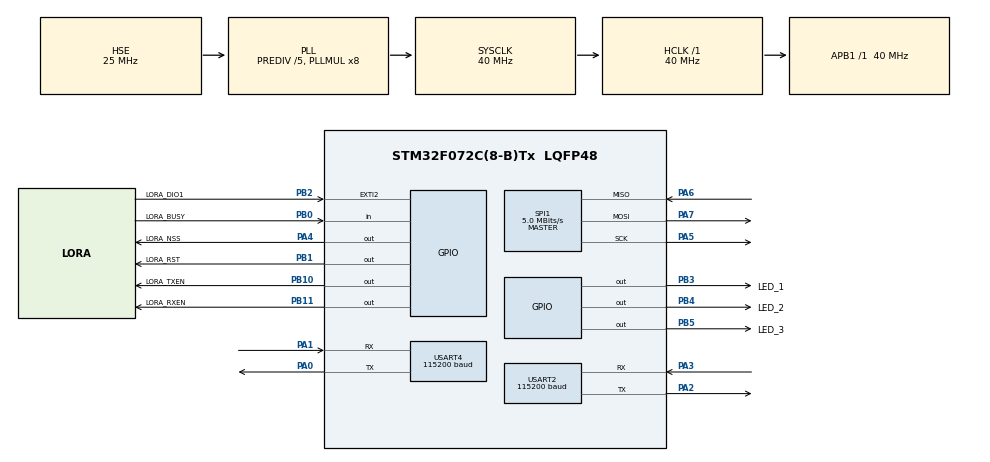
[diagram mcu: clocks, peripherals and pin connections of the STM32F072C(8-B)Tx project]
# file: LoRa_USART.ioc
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Dma.Request0=USART2_RX
Dma.Request1=USART2_TX
Dma.Request2=SPI1_RX
Dma.Request3=SPI1_TX
Dma.SPI1_RX.2.Direction=DMA_PERIPH_TO_MEMORY
Dma.SPI1_RX.2.Instance=DMA1_Channel2
Dma.SPI1_RX.2.MemDataAlignment=DMA_MDATAALIGN_BYTE
Dma.SPI1_RX.2.MemInc=DMA_MINC_ENABLE
Dma.SPI1_RX.2.Mode=DMA_NORMAL
Dma.SPI1_RX.2.PeriphDataAlignment=DMA_PDATAALIGN_BYTE
Dma.SPI1_RX.2.PeriphInc=DMA_PINC_DISABLE
Dma.SPI1_RX.2.Priority=DMA_PRIORITY_HIGH
Dma.SPI1_TX.3.Direction=DMA_MEMORY_TO_PERIPH
Dma.SPI1_TX.3.Instance=DMA1_Channel3
Dma.SPI1_TX.3.MemDataAlignment=DMA_MDATAALIGN_BYTE
Dma.SPI1_TX.3.MemInc=DMA_MINC_ENABLE
Dma.SPI1_TX.3.Mode=DMA_NORMAL
Dma.SPI1_TX.3.PeriphDataAlignment=DMA_PDATAALIGN_BYTE
Dma.SPI1_TX.3.PeriphInc=DMA_PINC_DISABLE
Dma.SPI1_TX.3.Priority=DMA_PRIORITY_HIGH
Dma.USART2_RX.0.Direction=DMA_PERIPH_TO_MEMORY
Dma.USART2_RX.0.Instance=DMA1_Channel5
Dma.USART2_RX.0.MemDataAlignment=DMA_MDATAALIGN_BYTE
Dma.USART2_RX.0.MemInc=DMA_MINC_ENABLE
Dma.USART2_RX.0.Mode=DMA_NORMAL
Dma.USART2_RX.0.PeriphDataAlignment=DMA_PDATAALIGN_BYTE
Dma.USART2_RX.0.PeriphInc=DMA_PINC_DISABLE
Dma.USART2_RX.0.Priority=DMA_PRIORITY_HIGH
Dma.USART2_TX.1.Direction=DMA_MEMORY_TO_PERIPH
Dma.USART2_TX.1.Instance=DMA1_Channel4
Dma.USART2_TX.1.MemDataAlignment=DMA_MDATAALIGN_BYTE
Dma.USART2_TX.1.MemInc=DMA_MINC_ENABLE
Dma.USART2_TX.1.Mode=DMA_NORMAL
Dma.USART2_TX.1.PeriphDataAlignment=DMA_PDATAALIGN_BYTE
Dma.USART2_TX.1.PeriphInc=DMA_PINC_DISABLE
Dma.USART2_TX.1.Priority=DMA_PRIORITY_HIGH
Mcu.Family=STM32F0
Mcu.Name=STM32F072C(8-B)Tx
Mcu.Package=LQFP48
NVIC.DMA1_Channel2_3_IRQn=true\:0\:0\:false\:false\:true\:false\:true\:true
NVIC.DMA1_Channel4_5_6_7_IRQn=true\:0\:0\:false\:false\:true\:false\:true\:true
NVIC.EXTI2_3_IRQn=true\:0\:0\:false\:false\:true\:true\:true\:true
NVIC.SPI1_IRQn=true\:0\:0\:false\:false\:true\:true\:true\:true
NVIC.USART2_IRQn=true\:0\:0\:false\:false\:true\:true\:true\:true
NVIC.USART3_4_IRQn=true\:0\:0\:false\:false\:true\:true\:true\:true
PA0.Mode=Asynchronous
PA0.Signal=USART4_TX
PA1.Mode=Asynchronous
PA1.Signal=USART4_RX
PA13.Mode=Serial_Wire
PA13.Signal=SYS_SWDIO
PA14.Mode=Serial_Wire
PA14.Signal=SYS_SWCLK
PA2.Mode=Asynchronous
PA2.Signal=USART2_TX
PA3.Mode=Asynchronous
PA3.Signal=USART2_RX
PA4.GPIO_Label=LORA_NSS
PA4.GPIO_Speed=GPIO_SPEED_FREQ_HIGH
PA4.Signal=GPIO_Output
PA5.Mode=Full_Duplex_Master
PA5.Signal=SPI1_SCK
PA6.Mode=Full_Duplex_Master
PA6.Signal=SPI1_MISO
PA7.Mode=Full_Duplex_Master
PA7.Signal=SPI1_MOSI
PB0.GPIO_Label=LORA_BUSY
PB0.Signal=GPIO_Input
PB1.GPIO_Label=LORA_RST
PB1.Signal=GPIO_Output
PB10.GPIO_Label=LORA_TXEN
PB10.GPIO_Speed=GPIO_SPEED_FREQ_HIGH
PB10.Signal=GPIO_Output
PB11.GPIO_Label=LORA_RXEN
PB11.GPIO_Speed=GPIO_SPEED_FREQ_HIGH
PB11.Signal=GPIO_Output
PB2.GPIO_Label=LORA_DIO1
PB2.Signal=GPXTI2
PB3.GPIO_Label=LED_1
PB3.Signal=GPIO_Output
PB4.GPIO_Label=LED_2
PB4.Signal=GPIO_Output
PB5.GPIO_Label=LED_3
PB5.Signal=GPIO_Output
PF0-OSC_IN.Mode=HSE-External-Oscillator
PF0-OSC_IN.Signal=RCC_OSC_IN
PF1-OSC_OUT.Mode=HSE-External-Oscillator
PF1-OSC_OUT.Signal=RCC_OSC_OUT
ProjectManager.HeapSize=0x200
ProjectManager.StackSize=0x400
ProjectManager.TargetToolchain=MDK-ARM V5.32
RCC.AHBFreq_Value=40000000
RCC.APB1Freq_Value=40000000
RCC.APB1TimFreq_Value=40000000
RCC.HCLKFreq_Value=40000000
RCC.HSE_VALUE=25000000
RCC.PLLDivider=RCC_PREDIV_DIV5
RCC.PLLMUL=RCC_PLL_MUL8
RCC.PLLSourceVirtual=RCC_PLLSOURCE_HSE
RCC.SYSCLKFreq_VALUE=40000000
RCC.SYSCLKSource=RCC_SYSCLKSOURCE_PLLCLK
SPI1.BaudRatePrescaler=SPI_BAUDRATEPRESCALER_8
SPI1.CalculateBaudRate=5.0 MBits/s
SPI1.DataSize=SPI_DATASIZE_8BIT
SPI1.Direction=SPI_DIRECTION_2LINES
SPI1.Mode=SPI_MODE_MASTER
SPI1.VirtualType=VM_MASTER
USART2.BaudRate=115200
USART2.VirtualMode-Asynchronous=VM_ASYNC
USART4.BaudRate=115200
USART4.VirtualMode-Asynchronous=VM_ASYNC
board=custom

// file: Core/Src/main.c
/* USER CODE BEGIN Header */
/**
  ******************************************************************************
  * @file           : main.c
  * @brief          : Main program body
  ******************************************************************************
  * @attention
  *
  * Copyright (c) 2026 STMicroelectronics.
  * All rights reserved.
  *
  * This software is licensed under terms that can be found in the LICENSE file
  * in the root directory of this software component.
  * If no LICENSE file comes with this software, it is provided AS-IS.
  *
  ******************************************************************************
  */
/* USER CODE END Header */
#include "main.h"
#include "dma.h"
#include "spi.h"
#include "usart.h"
#include "gpio.h"

/* USER CODE BEGIN Includes */
#include "app_bridge.h"
#include "myRadio.h"
#include "sx126x.h"
/* USER CODE END Includes */

void SystemClock_Config(void);

int main(void)
{

  /* MCU Configuration--------------------------------------------------------*/

  /* Reset of all peripherals, Initializes the Flash interface and the Systick. */
  HAL_Init();

  /* Configure the system clock */
  SystemClock_Config();

  /* Initialize all configured peripherals */
  MX_GPIO_Init();
  MX_DMA_Init();
  MX_SPI1_Init();
  MX_USART2_UART_Init();
  MX_USART4_UART_Init();
  /* USER CODE BEGIN 2 */

  /*--- Radio initialization ---*/
  myRadio_setChipType(DVTP_VGdd79S915X0M2);
  myRadio_init(0, (void*)Bridge_RadioCallback);

  /* Configure radio parameters (adjust as needed) */
  myRadio_setFrequency(915000000);
  myRadio_setTxPower(8);
  myRadio_setBaudrate(RF_BAUDRATE_62500);

  /* Initialize bridge: LED3 ON, start USART2 DMA RX */
  Bridge_Init();

  /* Enter continuous LoRa RX mode */
  myRadio_receiver();

  /* USER CODE END 2 */

  /* Infinite loop */
  while (1)
  {

    /* USER CODE BEGIN 3 */

    /* Process LoRa radio interrupts (must be called continuously) */
    myRadio_process();

    /* Process bridge logic (UART RX forwarding, LED timers) */
    Bridge_Process();

  }
  /* USER CODE END 3 */
}

void SystemClock_Config(void)
{
  RCC_OscInitTypeDef RCC_OscInitStruct = {0};
  RCC_ClkInitTypeDef RCC_ClkInitStruct = {0};
  RCC_PeriphCLKInitTypeDef PeriphClkInit = {0};

  /** Initializes the RCC Oscillators according to the specified parameters
  * in the RCC_OscInitTypeDef structure.
  */
  RCC_OscInitStruct.OscillatorType = RCC_OSCILLATORTYPE_HSE;
  RCC_OscInitStruct.HSEState = RCC_HSE_ON;
  RCC_OscInitStruct.PLL.PLLState = RCC_PLL_ON;
  RCC_OscInitStruct.PLL.PLLSource = RCC_PLLSOURCE_HSE;
  RCC_OscInitStruct.PLL.PLLMUL = RCC_PLL_MUL8;
  RCC_OscInitStruct.PLL.PREDIV = RCC_PREDIV_DIV5;
  if (HAL_RCC_OscConfig(&RCC_OscInitStruct) != HAL_OK)
  {
    Error_Handler();
  }

  /** Initializes the CPU, AHB and APB buses clocks
  */
  RCC_ClkInitStruct.ClockType = RCC_CLOCKTYPE_HCLK|RCC_CLOCKTYPE_SYSCLK
                              |RCC_CLOCKTYPE_PCLK1;
  RCC_ClkInitStruct.SYSCLKSource = RCC_SYSCLKSOURCE_PLLCLK;
  RCC_ClkInitStruct.AHBCLKDivider = RCC_SYSCLK_DIV1;
  RCC_ClkInitStruct.APB1CLKDivider = RCC_HCLK_DIV1;

  if (HAL_RCC_ClockConfig(&RCC_ClkInitStruct, FLASH_LATENCY_1) != HAL_OK)
  {
    Error_Handler();
  }
  PeriphClkInit.PeriphClockSelection = RCC_PERIPHCLK_USART2;
  PeriphClkInit.Usart2ClockSelection = RCC_USART2CLKSOURCE_PCLK1;
  if (HAL_RCCEx_PeriphCLKConfig(&PeriphClkInit) != HAL_OK)
  {
    Error_Handler();
  }
}

void Error_Handler(void)
{
  __disable_irq();
  while (1)
  {
  }
}
